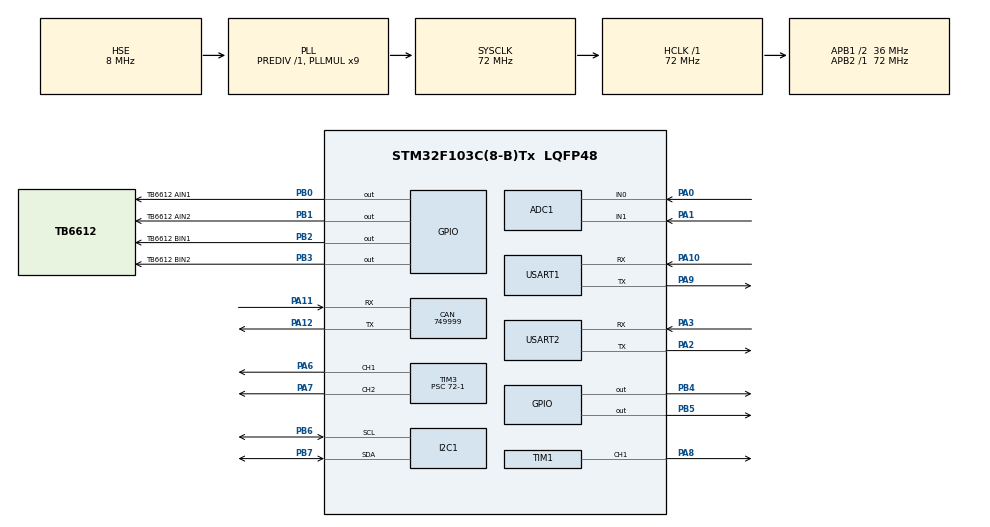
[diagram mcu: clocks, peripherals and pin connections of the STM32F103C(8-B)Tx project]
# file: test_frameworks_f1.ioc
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ADC1.Channel-1\#ChannelRegularConversion=ADC_CHANNEL_0
ADC1.NbrOfConversionFlag=1
ADC1.Rank-1\#ChannelRegularConversion=1
ADC1.SamplingTime-1\#ChannelRegularConversion=ADC_SAMPLETIME_1CYCLE_5
ADC1.master=1
CAN.CalculateBaudRate=749999
CAN.CalculateTimeBit=1333
CAN.CalculateTimeQuantum=444.44444444444446
Dma.Request0=USART1_TX
Dma.USART1_TX.0.Direction=DMA_MEMORY_TO_PERIPH
Dma.USART1_TX.0.Instance=DMA1_Channel4
Dma.USART1_TX.0.MemDataAlignment=DMA_MDATAALIGN_BYTE
Dma.USART1_TX.0.MemInc=DMA_MINC_ENABLE
Dma.USART1_TX.0.Mode=DMA_NORMAL
Dma.USART1_TX.0.PeriphDataAlignment=DMA_PDATAALIGN_BYTE
Dma.USART1_TX.0.PeriphInc=DMA_PINC_DISABLE
Dma.USART1_TX.0.Priority=DMA_PRIORITY_LOW
FREERTOS.Tasks01=defaultTask,24,128,StartDefaultTask,Default,NULL,Dynamic,NULL,NULL
FREERTOS.configENABLE_FPU=0
FREERTOS.configTOTAL_HEAP_SIZE=4096
FREERTOS.configUSE_PREEMPTION=1
I2C1.I2C_Mode=I2C_Fast
Mcu.Family=STM32F1
Mcu.Name=STM32F103C(8-B)Tx
Mcu.Package=LQFP48
NVIC.DMA1_Channel4_IRQn=true\:5\:0\:false\:false\:true\:true\:false\:true\:true
NVIC.PriorityGroup=NVIC_PRIORITYGROUP_4
NVIC.TIM4_IRQn=true\:15\:0\:false\:false\:true\:false\:false\:true\:true
NVIC.TimeBase=TIM4_IRQn
NVIC.TimeBaseIP=TIM4
NVIC.USART1_IRQn=true\:5\:0\:false\:false\:true\:true\:false\:true\:true
PA0-WKUP.Signal=ADCx_IN0
PA1.Signal=ADCx_IN1
PA10.Mode=Asynchronous
PA10.Signal=USART1_RX
PA11.Mode=CAN_Activate
PA11.Signal=CAN_RX
PA12.Mode=CAN_Activate
PA12.Signal=CAN_TX
PA13.Mode=Serial_Wire
PA13.Signal=SYS_JTMS-SWDIO
PA14.Mode=Serial_Wire
PA14.Signal=SYS_JTCK-SWCLK
PA2.Mode=Asynchronous
PA2.Signal=USART2_TX
PA3.Mode=Asynchronous
PA3.Signal=USART2_RX
PA6.Signal=S_TIM3_CH1
PA7.Signal=S_TIM3_CH2
PA8.Signal=S_TIM1_CH1
PA9.Mode=Asynchronous
PA9.Signal=USART1_TX
PB0.GPIO_Label=TB6612 AIN1
PB0.Signal=GPIO_Output
PB1.GPIO_Label=TB6612 AIN2
PB1.Signal=GPIO_Output
PB2.GPIO_Label=TB6612 BIN1
PB2.Signal=GPIO_Output
PB3.GPIO_Label=TB6612 BIN2
PB3.Signal=GPIO_Output
PB4.Signal=GPIO_Output
PB5.Signal=GPIO_Output
PB6.Mode=I2C
PB6.Signal=I2C1_SCL
PB7.Mode=I2C
PB7.Signal=I2C1_SDA
PD0-OSC_IN.Mode=HSE-External-Oscillator
PD0-OSC_IN.Signal=RCC_OSC_IN
PD1-OSC_OUT.Mode=HSE-External-Oscillator
PD1-OSC_OUT.Signal=RCC_OSC_OUT
ProjectManager.HeapSize=0x400
ProjectManager.StackSize=0x800
ProjectManager.TargetToolchain=CMake
RCC.ADCPresc=RCC_ADCPCLK2_DIV6
RCC.AHBFreq_Value=72000000
RCC.APB1CLKDivider=RCC_HCLK_DIV2
RCC.APB1Freq_Value=36000000
RCC.APB1TimFreq_Value=72000000
RCC.APB2Freq_Value=72000000
RCC.APB2TimFreq_Value=72000000
RCC.HCLKFreq_Value=72000000
RCC.PLLMUL=RCC_PLL_MUL9
RCC.PLLSourceVirtual=RCC_PLLSOURCE_HSE
RCC.SYSCLKFreq_VALUE=72000000
RCC.SYSCLKSource=RCC_SYSCLKSOURCE_PLLCLK
RCC.USBFreq_Value=72000000
SH.ADCx_IN0.0=ADC1_IN0,IN0
SH.ADCx_IN1.0=ADC1_IN1,IN1
SH.S_TIM1_CH1.0=TIM1_CH1,PWM Generation1 CH1
SH.S_TIM3_CH1.0=TIM3_CH1,PWM Generation1 CH1
SH.S_TIM3_CH2.0=TIM3_CH2,PWM Generation2 CH2
TIM1.AutoReloadPreload=TIM_AUTORELOAD_PRELOAD_ENABLE
TIM1.Channel-PWM\ Generation1\ CH1=TIM_CHANNEL_1
TIM1.Period=1000-1
TIM1.Prescaler=72-1
TIM3.AutoReloadPreload=TIM_AUTORELOAD_PRELOAD_ENABLE
TIM3.Channel-PWM\ Generation1\ CH1=TIM_CHANNEL_1
TIM3.Channel-PWM\ Generation2\ CH2=TIM_CHANNEL_2
TIM3.Period=1000-1
TIM3.Prescaler=72-1
USART1.VirtualMode=VM_ASYNC
USART2.VirtualMode=VM_ASYNC
VP_FREERTOS_VS_CMSIS_V2.Mode=CMSIS_V2
VP_SYS_VS_tim4.Mode=TIM4
VP_TIM1_VS_ClockSourceINT.Mode=Internal
VP_TIM3_VS_ClockSourceINT.Mode=Internal
board=custom

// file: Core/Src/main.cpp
/* USER CODE BEGIN Header */
/**
  ******************************************************************************
  * @file           : main.c
  * @brief          : Main program body
  ******************************************************************************
  * @attention
  *
  * Copyright (c) 2026 STMicroelectronics.
  * All rights reserved.
  *
  * This software is licensed under terms that can be found in the LICENSE file
  * in the root directory of this software component.
  * If no LICENSE file comes with this software, it is provided AS-IS.
  *
  ******************************************************************************
  */
/* USER CODE END Header */
#include "main.h"
#include "cmsis_os.h"
#include "adc.h"
#include "can.h"
#include "dma.h"
#include "i2c.h"
#include "tim.h"
#include "usart.h"
#include "gpio.h"

/* USER CODE BEGIN Includes */
#include "app/app.hpp"
/* USER CODE END Includes */

void SystemClock_Config(void);
void MX_FREERTOS_Init(void);

int main(void)
{

  /* MCU Configuration--------------------------------------------------------*/

  /* Reset of all peripherals, Initializes the Flash interface and the Systick. */
  HAL_Init();

  /* Configure the system clock */
  SystemClock_Config();

  /* Initialize all configured peripherals */
  MX_GPIO_Init();
  MX_DMA_Init();
  MX_ADC1_Init();
  MX_CAN_Init();
  MX_I2C1_Init();
  MX_TIM1_Init();
  MX_TIM3_Init();
  MX_USART1_UART_Init();
  MX_USART2_UART_Init();
  /* USER CODE BEGIN 2 */
  app::app_init();
  /* USER CODE END 2 */

  /* Init scheduler */
  osKernelInitialize();  /* Call init function for freertos objects (in cmsis_os2.c) */
  MX_FREERTOS_Init();

  /* Start scheduler */
  osKernelStart();

  /* We should never get here as control is now taken by the scheduler */

  /* Infinite loop */
  /* USER CODE BEGIN WHILE */
  while (1)
  {
    app::app_loop();
    /* USER CODE END WHILE */

  }
}

void SystemClock_Config(void)
{
  RCC_OscInitTypeDef RCC_OscInitStruct = {0};
  RCC_ClkInitTypeDef RCC_ClkInitStruct = {0};
  RCC_PeriphCLKInitTypeDef PeriphClkInit = {0};

  /** Initializes the RCC Oscillators according to the specified parameters
  * in the RCC_OscInitTypeDef structure.
  */
  RCC_OscInitStruct.OscillatorType = RCC_OSCILLATORTYPE_HSE;
  RCC_OscInitStruct.HSEState = RCC_HSE_ON;
  RCC_OscInitStruct.HSEPredivValue = RCC_HSE_PREDIV_DIV1;
  RCC_OscInitStruct.HSIState = RCC_HSI_ON;
  RCC_OscInitStruct.PLL.PLLState = RCC_PLL_ON;
  RCC_OscInitStruct.PLL.PLLSource = RCC_PLLSOURCE_HSE;
  RCC_OscInitStruct.PLL.PLLMUL = RCC_PLL_MUL9;
  if (HAL_RCC_OscConfig(&RCC_OscInitStruct) != HAL_OK)
  {
    Error_Handler();
  }

  /** Initializes the CPU, AHB and APB buses clocks
  */
  RCC_ClkInitStruct.ClockType = RCC_CLOCKTYPE_HCLK|RCC_CLOCKTYPE_SYSCLK
                              |RCC_CLOCKTYPE_PCLK1|RCC_CLOCKTYPE_PCLK2;
  RCC_ClkInitStruct.SYSCLKSource = RCC_SYSCLKSOURCE_PLLCLK;
  RCC_ClkInitStruct.AHBCLKDivider = RCC_SYSCLK_DIV1;
  RCC_ClkInitStruct.APB1CLKDivider = RCC_HCLK_DIV2;
  RCC_ClkInitStruct.APB2CLKDivider = RCC_HCLK_DIV1;

  if (HAL_RCC_ClockConfig(&RCC_ClkInitStruct, FLASH_LATENCY_2) != HAL_OK)
  {
    Error_Handler();
  }
  PeriphClkInit.PeriphClockSelection = RCC_PERIPHCLK_ADC;
  PeriphClkInit.AdcClockSelection = RCC_ADCPCLK2_DIV6;
  if (HAL_RCCEx_PeriphCLKConfig(&PeriphClkInit) != HAL_OK)
  {
    Error_Handler();
  }
}

void HAL_TIM_PeriodElapsedCallback(TIM_HandleTypeDef *htim)
{
  if (htim->Instance == TIM4)
  {
    HAL_IncTick();
  }
}

void Error_Handler(void)
{
  __disable_irq();
  while (1)
  {
  }
}
